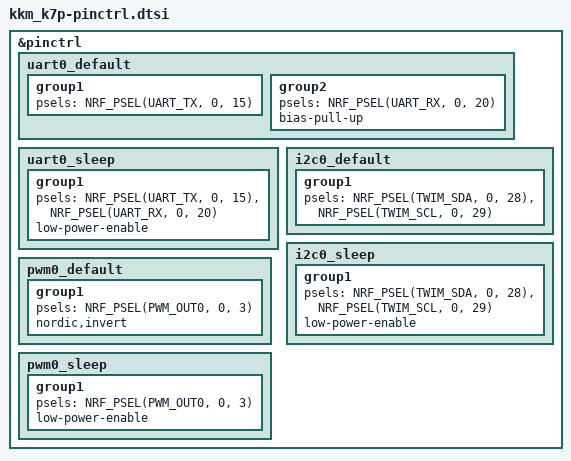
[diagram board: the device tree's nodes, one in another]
/*
 * Copyright (c) 2024 Blecon Ltd
 * SPDX-License-Identifier: Closed
 */

&pinctrl {
	uart0_default: uart0_default {
		group1 {
			psels = <NRF_PSEL(UART_TX, 0, 15)>;
		};
		group2 {
			psels = <NRF_PSEL(UART_RX, 0, 20)>;
			bias-pull-up;
		};
	};

	uart0_sleep: uart0_sleep {
		group1 {
			psels = <NRF_PSEL(UART_TX, 0, 15)>,
				<NRF_PSEL(UART_RX, 0, 20)>;
			low-power-enable;
		};
	};

	i2c0_default: i2c0_default {
		group1 {
			psels = <NRF_PSEL(TWIM_SDA, 0, 28)>,
				<NRF_PSEL(TWIM_SCL, 0, 29)>;
		};
	};

	i2c0_sleep: i2c0_sleep {
		group1 {
			psels = <NRF_PSEL(TWIM_SDA, 0, 28)>,
				<NRF_PSEL(TWIM_SCL, 0, 29)>;
			low-power-enable;
		};
	};

	pwm0_default: pwm0_default {
		group1 {
			psels = <NRF_PSEL(PWM_OUT0, 0, 3)>;
			nordic,invert;
		};
	};

	pwm0_sleep: pwm0_sleep {
		group1 {
			psels = <NRF_PSEL(PWM_OUT0, 0, 3)>;
			low-power-enable;
		};
	};
};
